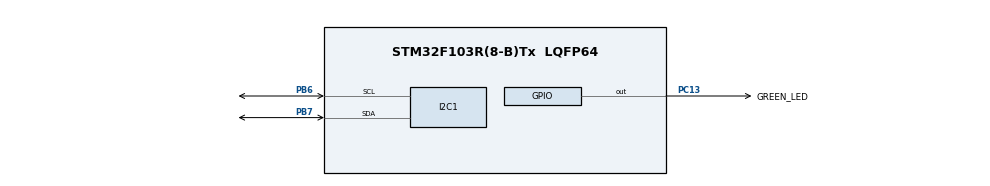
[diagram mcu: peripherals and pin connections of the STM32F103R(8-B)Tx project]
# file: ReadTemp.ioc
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I2C1.I2C_Mode=I2C_Fast
Mcu.Family=STM32F1
Mcu.Name=STM32F103R(8-B)Tx
Mcu.Package=LQFP64
NVIC.PriorityGroup=NVIC_PRIORITYGROUP_4
NVIC.RTC_IRQn=true\:0\:0\:false\:false\:true\:true\:true\:true
NVIC.TIM2_IRQn=true\:0\:0\:false\:false\:true\:true\:true\:true
PA13.Mode=Trace_Asynchronous_SW
PA13.Signal=SYS_JTMS-SWDIO
PA14.Mode=Trace_Asynchronous_SW
PA14.Signal=SYS_JTCK-SWCLK
PB3.Mode=Trace_Asynchronous_SW
PB3.Signal=SYS_JTDO-TRACESWO
PB6.Mode=I2C
PB6.Signal=I2C1_SCL
PB7.Mode=I2C
PB7.Signal=I2C1_SDA
PC13-TAMPER-RTC.GPIO_Label=GREEN_LED
PC13-TAMPER-RTC.Signal=GPIO_Output
ProjectManager.HeapSize=0x200
ProjectManager.StackSize=0x400
ProjectManager.TargetToolchain=STM32CubeIDE
RCC.APB1Freq_Value=8000000
RCC.APB2Freq_Value=8000000
RTC.Date=21
RTC.Hours=21
RTC.Minutes=47
RTC.Month=RTC_MONTH_OCTOBER
RTC.OutPut=RTC_OUTPUTSOURCE_NONE
TIM2.AutoReloadPreload=TIM_AUTORELOAD_PRELOAD_ENABLE
TIM2.ClockDivision=TIM_CLOCKDIVISION_DIV1
TIM2.Period=2001-1
TIM2.Prescaler=40001-1
TIM2.TIM_MasterSlaveMode=TIM_MASTERSLAVEMODE_ENABLE
VP_RTC_No_RTC_Output.Mode=RTC_OUT_NO
VP_RTC_VS_RTC_Activate.Mode=RTC_Enabled
VP_RTC_VS_RTC_Calendar.Mode=RTC_Calendar
VP_TIM2_VS_ClockSourceINT.Mode=Internal
board=custom

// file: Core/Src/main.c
/* USER CODE BEGIN Header */
/**
  ******************************************************************************
  * @file           : main.c
  * @brief          : Main program body
  ******************************************************************************
  * @attention
  *
  * <h2><center>&copy; Copyright (c) 2022 STMicroelectronics.
  * All rights reserved.</center></h2>
  *
  * This software component is licensed by ST under BSD 3-Clause license,
  * the "License"; You may not use this file except in compliance with the
  * License. You may obtain a copy of the License at:
  *                        opensource.org/licenses/BSD-3-Clause
  *
  ******************************************************************************
  */
/* USER CODE END Header */
#include "main.h"

/* USER CODE BEGIN Includes */
#include "DHT.h"

#include "ssd1306.h"
#include "fonts.h"
#include "test.h"

#include <stdlib.h>
#include <stdio.h>
#include <string.h>
/* USER CODE END Includes */

I2C_HandleTypeDef hi2c1;

RTC_HandleTypeDef hrtc;

TIM_HandleTypeDef htim2;

void SystemClock_Config(void);
static void MX_GPIO_Init(void);
static void MX_TIM2_Init(void);
static void MX_I2C1_Init(void);
static void MX_RTC_Init(void);
/* USER CODE BEGIN PFP */

void updateScreen(void);
/* USER CODE END PFP */

/* USER CODE BEGIN 0 */
DHT_DataTypedef DHT11_Data;
float Temperature, Humidity;
/* USER CODE END 0 */

int main(void)
{

  /* MCU Configuration--------------------------------------------------------*/

  /* Reset of all peripherals, Initializes the Flash interface and the Systick. */
  HAL_Init();

  /* Configure the system clock */
  SystemClock_Config();

  /* Initialize all configured peripherals */
  MX_GPIO_Init();
  MX_TIM2_Init();
  MX_I2C1_Init();
  MX_RTC_Init();
  /* USER CODE BEGIN 2 */
  SSD1306_Init (); // initialize the display
  HAL_TIM_PeriodElapsedCallback(&htim2); // Call the function to read temp a first time to get a result as soon the power one is done
  HAL_TIM_Base_Start_IT(&htim2);	// Start the Timer

  /* USER CODE END 2 */

  /* Infinite loop */
  while (1)
  {

  }
}

void SystemClock_Config(void)
{
  RCC_OscInitTypeDef RCC_OscInitStruct = {0};
  RCC_ClkInitTypeDef RCC_ClkInitStruct = {0};
  RCC_PeriphCLKInitTypeDef PeriphClkInit = {0};

  /** Initializes the RCC Oscillators according to the specified parameters
  * in the RCC_OscInitTypeDef structure.
  */
  RCC_OscInitStruct.OscillatorType = RCC_OSCILLATORTYPE_HSI|RCC_OSCILLATORTYPE_LSI;
  RCC_OscInitStruct.HSIState = RCC_HSI_ON;
  RCC_OscInitStruct.HSICalibrationValue = RCC_HSICALIBRATION_DEFAULT;
  RCC_OscInitStruct.LSIState = RCC_LSI_ON;
  RCC_OscInitStruct.PLL.PLLState = RCC_PLL_NONE;
  if (HAL_RCC_OscConfig(&RCC_OscInitStruct) != HAL_OK)
  {
    Error_Handler();
  }

  /** Initializes the CPU, AHB and APB buses clocks
  */
  RCC_ClkInitStruct.ClockType = RCC_CLOCKTYPE_HCLK|RCC_CLOCKTYPE_SYSCLK
                              |RCC_CLOCKTYPE_PCLK1|RCC_CLOCKTYPE_PCLK2;
  RCC_ClkInitStruct.SYSCLKSource = RCC_SYSCLKSOURCE_HSI;
  RCC_ClkInitStruct.AHBCLKDivider = RCC_SYSCLK_DIV1;
  RCC_ClkInitStruct.APB1CLKDivider = RCC_HCLK_DIV1;
  RCC_ClkInitStruct.APB2CLKDivider = RCC_HCLK_DIV1;

  if (HAL_RCC_ClockConfig(&RCC_ClkInitStruct, FLASH_LATENCY_0) != HAL_OK)
  {
    Error_Handler();
  }
  PeriphClkInit.PeriphClockSelection = RCC_PERIPHCLK_RTC;
  PeriphClkInit.RTCClockSelection = RCC_RTCCLKSOURCE_LSI;
  if (HAL_RCCEx_PeriphCLKConfig(&PeriphClkInit) != HAL_OK)
  {
    Error_Handler();
  }
}

static void MX_I2C1_Init(void)
{

  hi2c1.Instance = I2C1;
  hi2c1.Init.ClockSpeed = 400000;
  hi2c1.Init.DutyCycle = I2C_DUTYCYCLE_2;
  hi2c1.Init.OwnAddress1 = 0;
  hi2c1.Init.AddressingMode = I2C_ADDRESSINGMODE_7BIT;
  hi2c1.Init.DualAddressMode = I2C_DUALADDRESS_DISABLE;
  hi2c1.Init.OwnAddress2 = 0;
  hi2c1.Init.GeneralCallMode = I2C_GENERALCALL_DISABLE;
  hi2c1.Init.NoStretchMode = I2C_NOSTRETCH_DISABLE;
  if (HAL_I2C_Init(&hi2c1) != HAL_OK)
  {
    Error_Handler();
  }

}

static void MX_RTC_Init(void)
{

  RTC_TimeTypeDef sTime = {0};
  RTC_DateTypeDef DateToUpdate = {0};

  /** Initialize RTC Only
  */
  hrtc.Instance = RTC;
  hrtc.Init.AsynchPrediv = RTC_AUTO_1_SECOND;
  hrtc.Init.OutPut = RTC_OUTPUTSOURCE_NONE;
  if (HAL_RTC_Init(&hrtc) != HAL_OK)
  {
    Error_Handler();
  }

  /** Initialize RTC and set the Time and Date
  */
  sTime.Hours = 0x21;
  sTime.Minutes = 0x47;
  sTime.Seconds = 0x0;

  if (HAL_RTC_SetTime(&hrtc, &sTime, RTC_FORMAT_BCD) != HAL_OK)
  {
    Error_Handler();
  }
  DateToUpdate.WeekDay = RTC_WEEKDAY_MONDAY;
  DateToUpdate.Month = RTC_MONTH_OCTOBER;
  DateToUpdate.Date = 0x21;
  DateToUpdate.Year = 0x0;

  if (HAL_RTC_SetDate(&hrtc, &DateToUpdate, RTC_FORMAT_BCD) != HAL_OK)
  {
    Error_Handler();
  }

}

static void MX_TIM2_Init(void)
{

  TIM_ClockConfigTypeDef sClockSourceConfig = {0};
  TIM_MasterConfigTypeDef sMasterConfig = {0};

  htim2.Instance = TIM2;
  htim2.Init.Prescaler = 40001-1;
  htim2.Init.CounterMode = TIM_COUNTERMODE_UP;
  htim2.Init.Period = 2001-1;
  htim2.Init.ClockDivision = TIM_CLOCKDIVISION_DIV1;
  htim2.Init.AutoReloadPreload = TIM_AUTORELOAD_PRELOAD_ENABLE;
  if (HAL_TIM_Base_Init(&htim2) != HAL_OK)
  {
    Error_Handler();
  }
  sClockSourceConfig.ClockSource = TIM_CLOCKSOURCE_INTERNAL;
  if (HAL_TIM_ConfigClockSource(&htim2, &sClockSourceConfig) != HAL_OK)
  {
    Error_Handler();
  }
  sMasterConfig.MasterOutputTrigger = TIM_TRGO_RESET;
  sMasterConfig.MasterSlaveMode = TIM_MASTERSLAVEMODE_ENABLE;
  if (HAL_TIMEx_MasterConfigSynchronization(&htim2, &sMasterConfig) != HAL_OK)
  {
    Error_Handler();
  }

}

static void MX_GPIO_Init(void)
{
  GPIO_InitTypeDef GPIO_InitStruct = {0};

  /* GPIO Ports Clock Enable */
  __HAL_RCC_GPIOC_CLK_ENABLE();
  __HAL_RCC_GPIOA_CLK_ENABLE();
  __HAL_RCC_GPIOB_CLK_ENABLE();

  /*Configure GPIO pin Output Level */
  HAL_GPIO_WritePin(GREEN_LED_GPIO_Port, GREEN_LED_Pin, GPIO_PIN_RESET);

  /*Configure GPIO pin : GREEN_LED_Pin */
  GPIO_InitStruct.Pin = GREEN_LED_Pin;
  GPIO_InitStruct.Mode = GPIO_MODE_OUTPUT_PP;
  GPIO_InitStruct.Pull = GPIO_NOPULL;
  GPIO_InitStruct.Speed = GPIO_SPEED_FREQ_LOW;
  HAL_GPIO_Init(GREEN_LED_GPIO_Port, &GPIO_InitStruct);

}

/* USER CODE BEGIN 4 */
// Timer IT handler
void HAL_TIM_PeriodElapsedCallback(TIM_HandleTypeDef *htim){
	  // Check which version of the timer triggered this callback and toggle LED
	//Timer Time = Clk * prescaler * (autoreload + 1)
	  if (htim == &htim2 )
	  {
		  //HAL_GPIO_WritePin(GREEN_LED_GPIO_Port, GREEN_LED_Pin, HAL_GPIO_ReadPin(COLD_PIN_GPIO_Port, COLD_PIN_Pin));
		  HAL_GPIO_TogglePin(GREEN_LED_GPIO_Port, GREEN_LED_Pin);
		  DHT_GetData(&DHT11_Data);
		  Temperature = DHT11_Data.Temperature;
		  Humidity = DHT11_Data.Humidity;
		  updateScreen();
	  }
}

void updateScreen(void){
	char line[20];
	RTC_TimeTypeDef sTime = {0};
	HAL_RTC_GetTime(&hrtc, &sTime, RTC_FORMAT_BCD);

	sprintf(line, "%3.fC %2.f",Temperature, Humidity);
	SSD1306_GotoXY (5, 10);
	SSD1306_Puts (line, &Font_11x18, 1);
	SSD1306_UpdateScreen(); // update screen

	sprintf(line, "%x:%x:%x", sTime.Hours, sTime.Minutes, sTime.Seconds);
	SSD1306_GotoXY (5, 40);
	SSD1306_Puts (line, &Font_11x18, 1);
	SSD1306_UpdateScreen(); // update screen

}
/* USER CODE END 4 */

void Error_Handler(void)
{
  __disable_irq();
  while (1)
  {
  }
}
